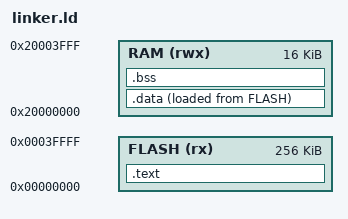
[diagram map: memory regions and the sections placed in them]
MEMORY
{
    FLASH (rx) : ORIGIN = 0x00000000, LENGTH = 256K
    RAM (rwx)  : ORIGIN = 0x20000000, LENGTH = 16K
}

ENTRY(Reset_Handler)

SECTIONS
{
    .text : {
        KEEP(*(.isr_vector))  /* 中断向量表放在最前 */
        *(.text)
        *(.text*)
        *(.rodata)
        *(.rodata*)
    } > FLASH

    _sidata = LOADADDR(.data);

    .data : {
        _sdata = .;
        *(.data)
        *(.data*)
        _edata = .;
    } > RAM AT > FLASH

    .bss : {
        _sbss = .;
        *(.bss)
        *(.bss*)
        *(COMMON)
        _ebss = .;
    } > RAM

    /DISCARD/ : {
        *(.comment)
        *(.ARM.attributes)
    }
}
